# HC32F334J8UI register map
File version: 1.0
CPU: CM4 r0p1, little endian, MPU, FPU, 4 interrupt priority bits
Registers are 32-bit, read-write, reset 0x0 unless marked. A register's access mark holds for its fields unless they carry their own. Offsets are from the block's base; [hi:lo] are bit positions; {n}, {i} and the like mark numbered series.

## HRPWM_COMMON
Base 0x4003C2F0
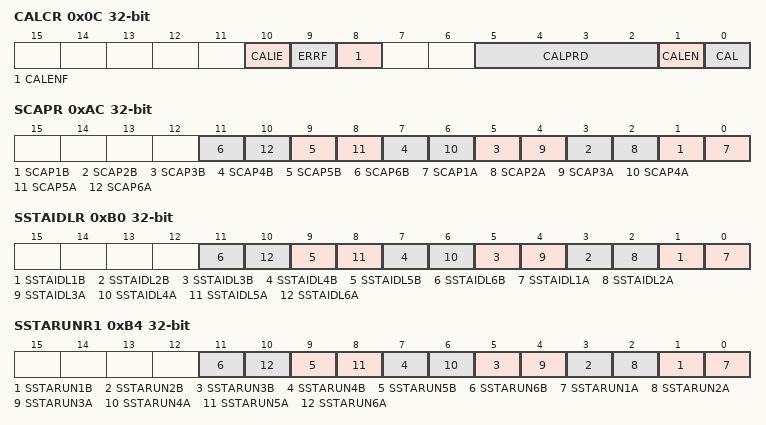
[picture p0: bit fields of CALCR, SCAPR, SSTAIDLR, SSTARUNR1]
0x0C CALCR
  [10] CALIE, [9] ERRF, [8] CALENF, [5:2] CALPRD, [1] CALEN, [0] CAL
0xAC SCAPR wo
  [2n-1] SCAP{n}B (n=1..6), [2n-2] SCAP{n}A (n=1..6)
0xB0 SSTAIDLR wo
  [2n-1] SSTAIDL{n}B (n=1..6), [2n-2] SSTAIDL{n}A (n=1..6)
0xB4 SSTARUNR1
  [2n-1] SSTARUN{n}B (n=1..6), [2n-2] SSTARUN{n}A (n=1..6)
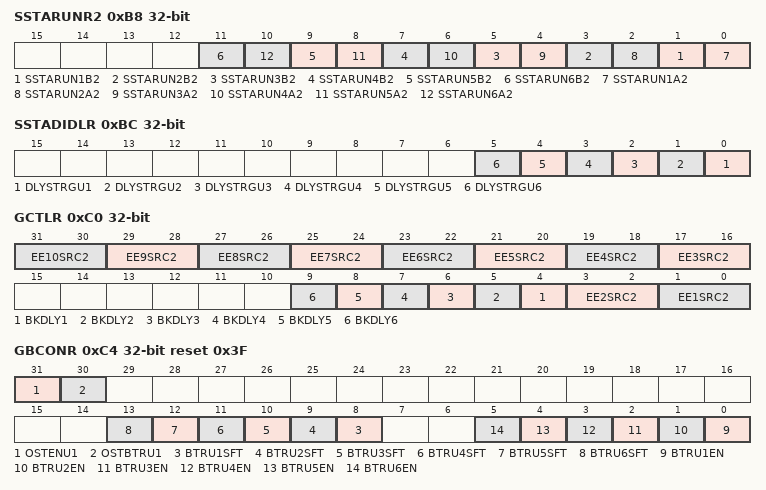
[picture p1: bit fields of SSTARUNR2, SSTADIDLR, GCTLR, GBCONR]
0xB8 SSTARUNR2 wo
  [2n-1] SSTARUN{n}B2 (n=1..6), [2n-2] SSTARUN{n}A2 (n=1..6)
0xBC SSTADIDLR wo
  [n-1] DLYSTRGU{n} (n=1..6)
0xC0 GCTLR
  [2n+11:2n+10] EE{n}SRC2 (n=3..10), [n+3] BKDLY{n} (n=1..6), [3:2] EE2SRC2, [1:0] EE1SRC2
0xC4 GBCONR reset 0x3F
  [31] OSTENU1, [30] OSTBTRU1 wo, [n+7] BTRU{n}SFT (n=1..6), [n-1] BTRU{n}EN (n=1..6)
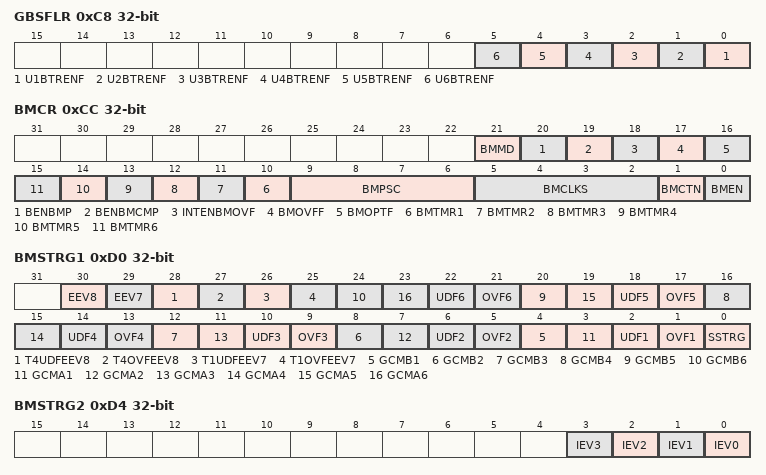
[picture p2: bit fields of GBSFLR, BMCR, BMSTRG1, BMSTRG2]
0xC8 GBSFLR
  [n-1] U{n}BTRENF (n=1..6)
0xCC BMCR
  [21] BMMD, [20] BENBMP, [19] BENBMCMP, [18] INTENBMOVF, [17] BMOVFF, [16] BMOPTF, [n+9] BMTMR{n} (n=1..6), [9:6] BMPSC, [5:2] BMCLKS, [1] BMCTN, [0] BMEN
0xD0 BMSTRG1
  [30] EEV8, [29] EEV7, [28] T4UDFEEV8, [27] T4OVFEEV8, [26] T1UDFEEV7, [25] T1OVFEEV7, [4n] GCMB{n} (n=1..6), [4n-1] GCMA{n} (n=1..6), [4n-2] UDF{n} (n=1..6), [4n-3] OVF{n} (n=1..6), [0] SSTRG wo
0xD4 BMSTRG2
  [n] IEV{n} (n=0..3)
0xD8 BMPERAR
  [15:0] BMPERAR
0xDC BMPERBR
  [15:0] BMPERBR
0xE0 BMCMAR
  [15:0] BMCMAR
0xE4 BMCMBR
  [15:0] BMCMBR
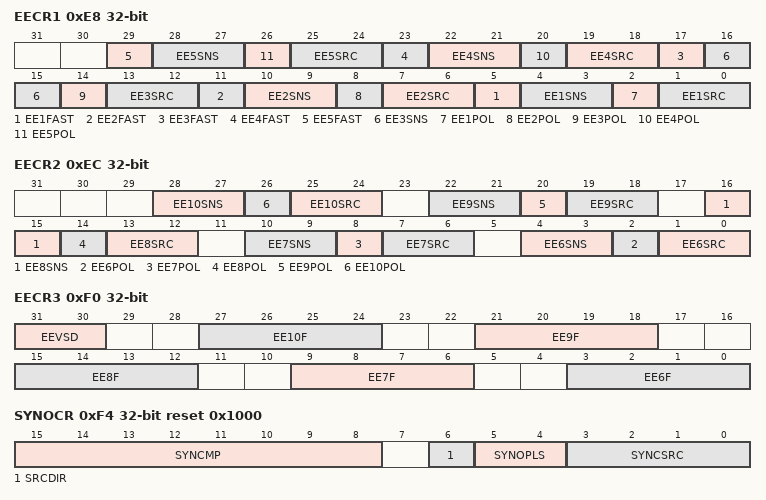
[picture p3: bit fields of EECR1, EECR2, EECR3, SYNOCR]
0xE8 EECR1
  [6n-1] EE{n}FAST (n=1..5), [6n-2:6n-3] EE{n}SNS (n=1..5), [6n-4] EE{n}POL (n=1..5), [6n-5:6n-6] EE{n}SRC (n=1..5)
0xEC EECR2
  [6n-32:6n-33] EE{n}SNS (n=6..10), [6n-34] EE{n}POL (n=6..10), [6n-35:6n-36] EE{n}SRC (n=6..10)
0xF0 EECR3
  [31:30] EEVSD, [6n-33:6n-36] EE{n}F (n=6..10)
0xF4 SYNOCR reset 0x1000
  [15:8] SYNCMP, [6] SRCDIR, [5:4] SYNOPLS, [3:0] SYNCSRC
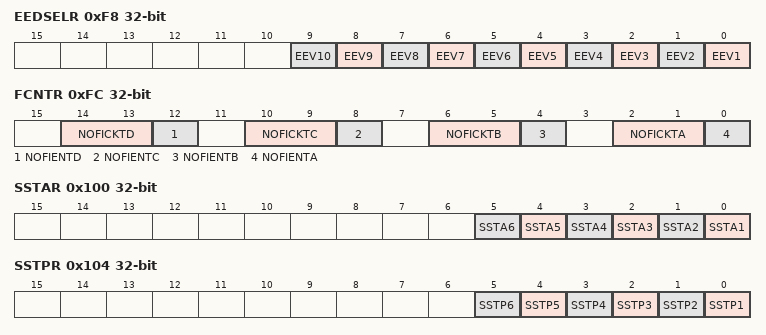
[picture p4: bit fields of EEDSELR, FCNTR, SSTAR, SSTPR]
0xF8 EEDSELR
  [n-1] EEV{n} (n=1..10)
0xFC FCNTR
  [14:13] NOFICKTD, [12] NOFIENTD, [10:9] NOFICKTC, [8] NOFIENTC, [6:5] NOFICKTB, [4] NOFIENTB, [2:1] NOFICKTA, [0] NOFIENTA
0x100 SSTAR
  [n-1] SSTA{n} (n=1..6)
0x104 SSTPR wo
  [n-1] SSTP{n} (n=1..6)
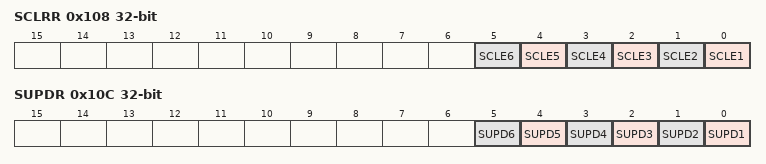
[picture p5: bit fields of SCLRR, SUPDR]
0x108 SCLRR wo
  [n-1] SCLE{n} (n=1..6)
0x10C SUPDR wo
  [n-1] SUPD{n} (n=1..6)

## I2C
Base 0x4003B400
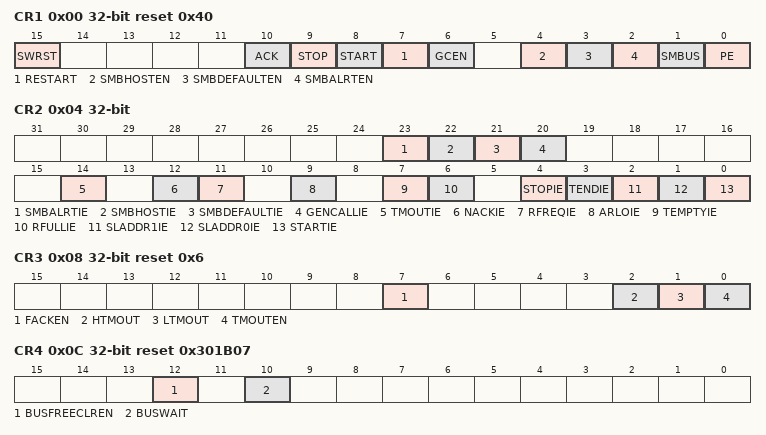
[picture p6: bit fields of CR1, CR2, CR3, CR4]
0x00 CR1 reset 0x40
  [15] SWRST, [10] ACK, [9] STOP, [8] START, [7] RESTART, [6] GCEN, [4] SMBHOSTEN, [3] SMBDEFAULTEN, [2] SMBALRTEN, [1] SMBUS, [0] PE
0x04 CR2
  [23] SMBALRTIE, [22] SMBHOSTIE, [21] SMBDEFAULTIE, [20] GENCALLIE, [14] TMOUTIE, [12] NACKIE, [11] RFREQIE, [9] ARLOIE, [7] TEMPTYIE, [6] RFULLIE, [4] STOPIE, [3] TENDIE, [2] SLADDR1IE, [1] SLADDR0IE, [0] STARTIE
0x08 CR3 reset 0x6
  [7] FACKEN, [2] HTMOUT, [1] LTMOUT, [0] TMOUTEN
0x0C CR4 reset 0x301B07
  [12] BUSFREECLREN, [10] BUSWAIT
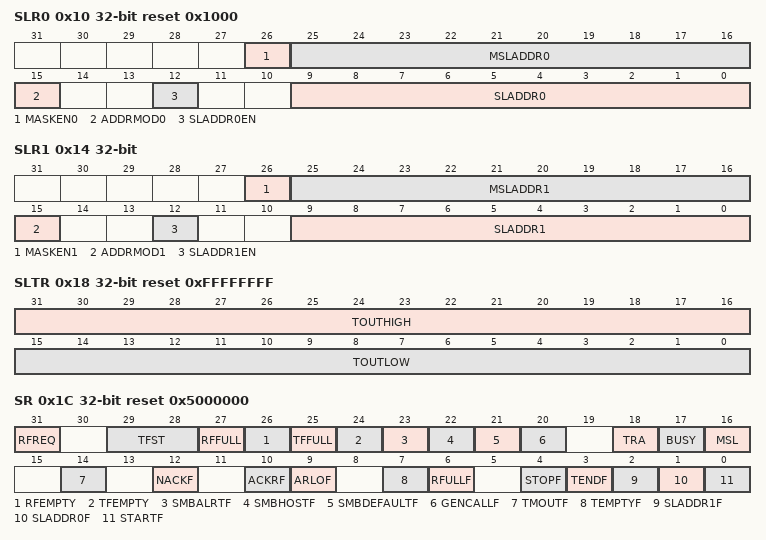
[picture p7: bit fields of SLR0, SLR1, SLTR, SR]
0x10 SLR0 reset 0x1000
  [26] MASKEN0, [25:16] MSLADDR0, [15] ADDRMOD0, [12] SLADDR0EN, [9:0] SLADDR0
0x14 SLR1
  [26] MASKEN1, [25:16] MSLADDR1, [15] ADDRMOD1, [12] SLADDR1EN, [9:0] SLADDR1
0x18 SLTR reset 0xFFFFFFFF
  [31:16] TOUTHIGH, [15:0] TOUTLOW
0x1C SR reset 0x5000000
  [31] RFREQ, [29:28] TFST, [27] RFFULL, [26] RFEMPTY, [25] TFFULL, [24] TFEMPTY, [23] SMBALRTF, [22] SMBHOSTF, [21] SMBDEFAULTF, [20] GENCALLF, [18] TRA, [17] BUSY, [16] MSL, [14] TMOUTF, [12] NACKF, [10] ACKRF, [9] ARLOF, [7] TEMPTYF, [6] RFULLF, [4] STOPF, [3] TENDF, [2] SLADDR1F, [1] SLADDR0F, [0] STARTF
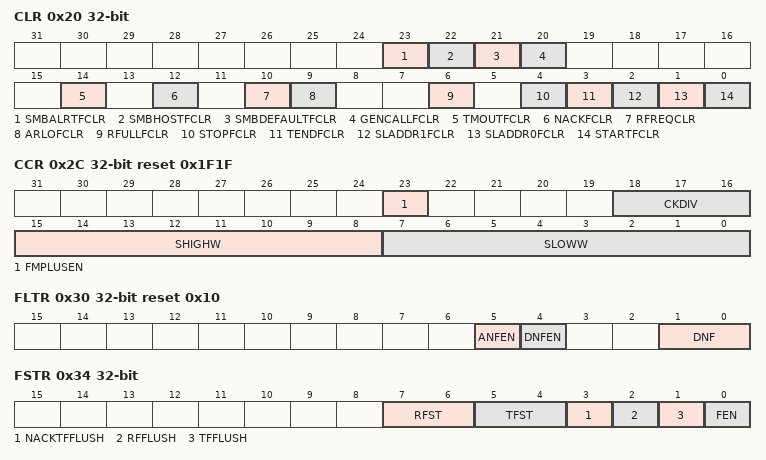
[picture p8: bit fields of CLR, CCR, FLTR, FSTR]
0x20 CLR wo
  [23] SMBALRTFCLR, [22] SMBHOSTFCLR, [21] SMBDEFAULTFCLR, [20] GENCALLFCLR, [14] TMOUTFCLR, [12] NACKFCLR, [10] RFREQCLR, [9] ARLOFCLR, [6] RFULLFCLR, [4] STOPFCLR, [3] TENDFCLR, [2] SLADDR1FCLR, [1] SLADDR0FCLR, [0] STARTFCLR
0x24 DTR 8-bit wo reset 0xFF
0x28 DRR 8-bit ro
0x2C CCR reset 0x1F1F
  [23] FMPLUSEN, [18:16] CKDIV, [15:8] SHIGHW, [7:0] SLOWW
0x30 FLTR reset 0x10
  [5] ANFEN, [4] DNFEN, [1:0] DNF
0x34 FSTR
  [7:6] RFST, [5:4] TFST, [3] NACKTFFLUSH, [2] RFFLUSH, [1] TFFLUSH, [0] FEN
0x38 SLVADDR
  [9:0] SLVADRR

## ICG
Base 0x00000400
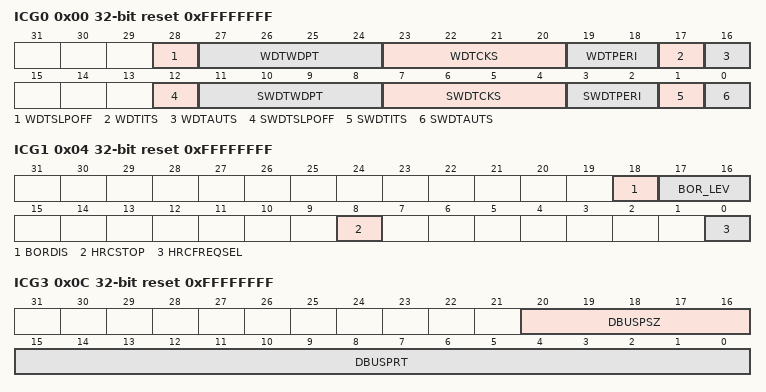
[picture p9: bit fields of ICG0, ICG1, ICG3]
0x00 ICG0 ro reset 0xFFFFFFFF
  [28] WDTSLPOFF, [27:24] WDTWDPT, [23:20] WDTCKS, [19:18] WDTPERI, [17] WDTITS, [16] WDTAUTS, [12] SWDTSLPOFF, [11:8] SWDTWDPT, [7:4] SWDTCKS, [3:2] SWDTPERI, [1] SWDTITS, [0] SWDTAUTS
0x04 ICG1 ro reset 0xFFFFFFFF
  [18] BORDIS, [17:16] BOR_LEV, [8] HRCSTOP, [0] HRCFREQSEL
0x0C ICG3 ro reset 0xFFFFFFFF
  [20:16] DBUSPSZ, [15:0] DBUSPRT
